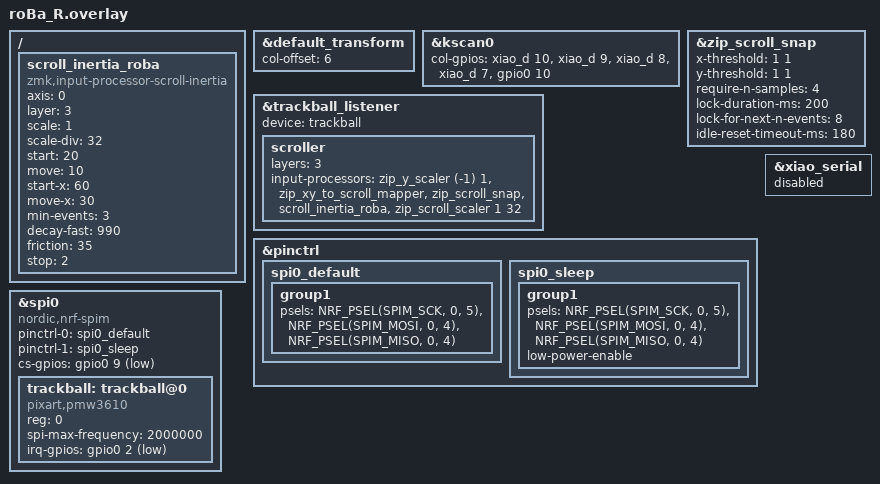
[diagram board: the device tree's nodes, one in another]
#include <input/processors.dtsi>
#include <scroll-snap.dtsi>
#include "roBa.dtsi"

&default_transform {
    col-offset = <6>;
};

&kscan0 {
        col-gpios
            = <&xiao_d 10 GPIO_ACTIVE_HIGH>
            , <&xiao_d 9 GPIO_ACTIVE_HIGH>
            , <&xiao_d 8 GPIO_ACTIVE_HIGH>
            , <&xiao_d 7 GPIO_ACTIVE_HIGH>
            , <&gpio0 10 GPIO_ACTIVE_HIGH>
            ;
};

/ {
    scroll_inertia_roba: scroll_inertia_roba {
        compatible = "zmk,input-processor-scroll-inertia";
        #input-processor-cells = <0>;

        // 縦横ともにスクロール可能
        axis = <0>;
        layer = <3>;

        scale = <1>;
        scale-div = <32>;

        // 縦スクロール：発動しやすい
        start = <20>;
        move = <10>;

        // 横スクロール：発動しにくい
        start-x = <60>;
        move-x = <30>;

        // 縦横共通
        min-events = <3>;

        // 慣性の減速設定
        decay-fast = <990>;
        friction = <35>;
        stop = <2>;
    };
};

&zip_scroll_snap {
    // 縦横の成分が1:1を境に方向判定
    x-threshold = <1 1>;
    y-threshold = <1 1>;

    // 方向判定に使うイベント数
    require-n-samples = <4>;

    // 判定した方向を保持
    lock-duration-ms = <200>;
    lock-for-next-n-events = <8>;

    // 入力が途切れたら判定をリセット
    idle-reset-timeout-ms = <180>;
};

&trackball_listener {
    status = "okay";
    device = <&trackball>;

    scroller {
        layers = <3>;
        input-processors = <
            &zip_y_scaler (-1) 1
            &zip_xy_to_scroll_mapper
            &zip_scroll_snap
            &scroll_inertia_roba
            &zip_scroll_scaler 1 32
        >;
    };
};

&pinctrl {
    spi0_default: spi0_default {
        group1 {
            psels = <NRF_PSEL(SPIM_SCK, 0, 5)>,
                <NRF_PSEL(SPIM_MOSI, 0, 4)>,
                <NRF_PSEL(SPIM_MISO, 0, 4)>;
        };
    };

    spi0_sleep: spi0_sleep {
        group1 {
            psels = <NRF_PSEL(SPIM_SCK, 0, 5)>,
                <NRF_PSEL(SPIM_MOSI, 0, 4)>,
                <NRF_PSEL(SPIM_MISO, 0, 4)>;
            low-power-enable;
        };
    };
};

&xiao_serial { status = "disabled"; };

&spi0 {
    status = "okay";
    compatible = "nordic,nrf-spim";
    pinctrl-0 = <&spi0_default>;
    pinctrl-1 = <&spi0_sleep>;
    pinctrl-names = "default", "sleep";
    cs-gpios = <&gpio0 9 GPIO_ACTIVE_LOW>;

    trackball: trackball@0 {
        status = "okay";
        compatible = "pixart,pmw3610";
        reg = <0>;
        spi-max-frequency = <2000000>;
        irq-gpios = <&gpio0 2 (GPIO_ACTIVE_LOW | GPIO_PULL_UP)>;
    };
};
